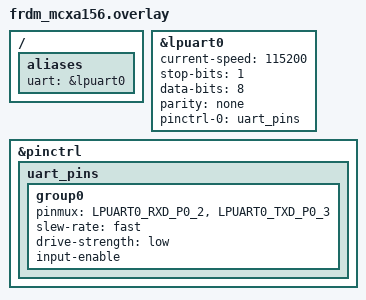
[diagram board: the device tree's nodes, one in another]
/ {
    aliases {
        uart = &lpuart0;
    };  
};

/*configure the uart 0, 115200 bauds, 8N1*/
&lpuart0 {
    status = "okay";
    current-speed = <115200>;
    stop-bits = "1";
    data-bits = <8>;
    parity = "none";
    pinctrl-0 = <&uart_pins>;
	pinctrl-names = "default";
};

/*configure uart pins as Tx and Rx pins*/
&pinctrl {
	uart_pins: uart_pins {
		group0 {
			pinmux = <LPUART0_RXD_P0_2>, <LPUART0_TXD_P0_3>;
            slew-rate = "fast";
			drive-strength = "low";
			input-enable;
        };
    };
};
